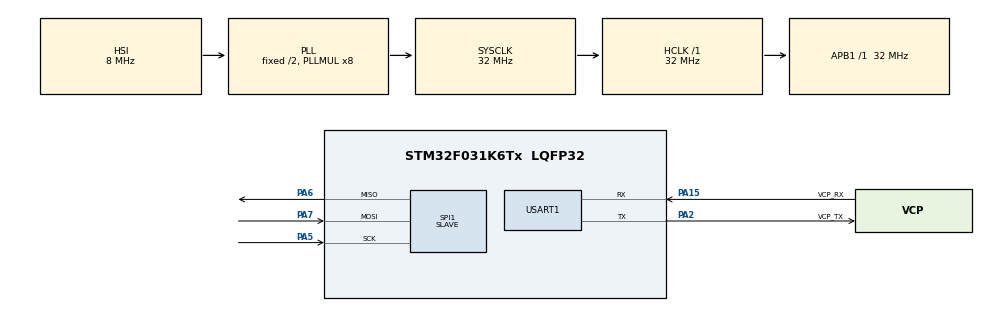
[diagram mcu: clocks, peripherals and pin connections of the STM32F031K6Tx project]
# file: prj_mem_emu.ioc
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Mcu.Family=STM32F0
Mcu.Name=STM32F031K6Tx
Mcu.Package=LQFP32
PA13.GPIO_Label=SWDIO
PA13.Mode=Serial_Wire
PA13.Signal=SYS_SWDIO
PA14.GPIO_Label=SWCLK
PA14.Mode=Serial_Wire
PA14.Signal=SYS_SWCLK
PA15.GPIO_Label=VCP_RX
PA15.Mode=Asynchronous
PA15.Signal=USART1_RX
PA2.GPIO_Label=VCP_TX
PA2.Mode=Asynchronous
PA2.Signal=USART1_TX
PA5.Mode=Full_Duplex_Slave
PA5.Signal=SPI1_SCK
PA6.Mode=Full_Duplex_Slave
PA6.Signal=SPI1_MISO
PA7.Mode=Full_Duplex_Slave
PA7.Signal=SPI1_MOSI
PF0-OSC_IN.Mode=HSE-External-Clock-Source
PF0-OSC_IN.Signal=RCC_OSC_IN
ProjectManager.HeapSize=0x200
ProjectManager.StackSize=0x400
ProjectManager.TargetToolchain=STM32CubeIDE
RCC.AHBFreq_Value=32000000
RCC.APB1Freq_Value=32000000
RCC.APB1TimFreq_Value=32000000
RCC.HCLKFreq_Value=32000000
RCC.PLLMUL=RCC_PLL_MUL8
RCC.SYSCLKFreq_VALUE=32000000
RCC.SYSCLKSource=RCC_SYSCLKSOURCE_PLLCLK
SPI1.DataSize=SPI_DATASIZE_8BIT
SPI1.Direction=SPI_DIRECTION_2LINES
SPI1.Mode=SPI_MODE_SLAVE
SPI1.VirtualType=VM_SLAVE
USART1.VirtualMode-Asynchronous=VM_ASYNC
board=NUCLEO-F031K6

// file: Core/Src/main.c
/* USER CODE BEGIN Header */
/**
  ******************************************************************************
  * @file           : main.c
  * @brief          : Main program body
  ******************************************************************************
  * @attention
  *
  * Copyright (c) 2023 STMicroelectronics.
  * All rights reserved.
  *
  * This software is licensed under terms that can be found in the LICENSE file
  * in the root directory of this software component.
  * If no LICENSE file comes with this software, it is provided AS-IS.
  *
  ******************************************************************************
  */
/* USER CODE END Header */
#include "main.h"

SPI_HandleTypeDef hspi1;

UART_HandleTypeDef huart1;

void SystemClock_Config(void);
static void MX_GPIO_Init(void);
static void MX_USART1_UART_Init(void);
static void MX_SPI1_Init(void);

/* USER CODE BEGIN 0 */
#define MEM_SIZE (256U)
/* USER CODE END 0 */

int main(void)
{
  /* USER CODE BEGIN 1 */
	uint8_t mem[MEM_SIZE];
	uint8_t rxdata[3];
	uint32_t index = 0;
  /* USER CODE END 1 */

  /* MCU Configuration--------------------------------------------------------*/

  /* Reset of all peripherals, Initializes the Flash interface and the Systick. */
  HAL_Init();

  /* Configure the system clock */
  SystemClock_Config();

  /* Initialize all configured peripherals */
  MX_GPIO_Init();
  MX_USART1_UART_Init();
  MX_SPI1_Init();

  /* Infinite loop */
  /* USER CODE BEGIN WHILE */
  while (1)
  {
	  HAL_SPI_Receive(&hspi1, rxdata, 2, HAL_MAX_DELAY);
	  if(rxdata[0] == 0x02){
		  HAL_SPI_Receive(&hspi1, rxdata + 2, 1, HAL_MAX_DELAY);
		  mem[rxdata[1] % MEM_SIZE] = rxdata[2];
	  }else if(rxdata[0] == 0x03){
		  HAL_SPI_Transmit(&hspi1, &(mem[rxdata[1] % MEM_SIZE]), 1, HAL_MAX_DELAY);
	  }
    /* USER CODE END WHILE */

  }
}

void SystemClock_Config(void)
{
  RCC_OscInitTypeDef RCC_OscInitStruct = {0};
  RCC_ClkInitTypeDef RCC_ClkInitStruct = {0};
  RCC_PeriphCLKInitTypeDef PeriphClkInit = {0};

  /** Initializes the RCC Oscillators according to the specified parameters
  * in the RCC_OscInitTypeDef structure.
  */
  RCC_OscInitStruct.OscillatorType = RCC_OSCILLATORTYPE_HSI;
  RCC_OscInitStruct.HSIState = RCC_HSI_ON;
  RCC_OscInitStruct.HSICalibrationValue = RCC_HSICALIBRATION_DEFAULT;
  RCC_OscInitStruct.PLL.PLLState = RCC_PLL_ON;
  RCC_OscInitStruct.PLL.PLLSource = RCC_PLLSOURCE_HSI;
  RCC_OscInitStruct.PLL.PLLMUL = RCC_PLL_MUL8;
  RCC_OscInitStruct.PLL.PREDIV = RCC_PREDIV_DIV1;
  if (HAL_RCC_OscConfig(&RCC_OscInitStruct) != HAL_OK)
  {
    Error_Handler();
  }

  /** Initializes the CPU, AHB and APB buses clocks
  */
  RCC_ClkInitStruct.ClockType = RCC_CLOCKTYPE_HCLK|RCC_CLOCKTYPE_SYSCLK
                              |RCC_CLOCKTYPE_PCLK1;
  RCC_ClkInitStruct.SYSCLKSource = RCC_SYSCLKSOURCE_PLLCLK;
  RCC_ClkInitStruct.AHBCLKDivider = RCC_SYSCLK_DIV1;
  RCC_ClkInitStruct.APB1CLKDivider = RCC_HCLK_DIV1;

  if (HAL_RCC_ClockConfig(&RCC_ClkInitStruct, FLASH_LATENCY_1) != HAL_OK)
  {
    Error_Handler();
  }
  PeriphClkInit.PeriphClockSelection = RCC_PERIPHCLK_USART1;
  PeriphClkInit.Usart1ClockSelection = RCC_USART1CLKSOURCE_PCLK1;
  if (HAL_RCCEx_PeriphCLKConfig(&PeriphClkInit) != HAL_OK)
  {
    Error_Handler();
  }
}

static void MX_SPI1_Init(void)
{

  /* SPI1 parameter configuration*/
  hspi1.Instance = SPI1;
  hspi1.Init.Mode = SPI_MODE_SLAVE;
  hspi1.Init.Direction = SPI_DIRECTION_2LINES;
  hspi1.Init.DataSize = SPI_DATASIZE_8BIT;
  hspi1.Init.CLKPolarity = SPI_POLARITY_LOW;
  hspi1.Init.CLKPhase = SPI_PHASE_1EDGE;
  hspi1.Init.NSS = SPI_NSS_SOFT;
  hspi1.Init.FirstBit = SPI_FIRSTBIT_MSB;
  hspi1.Init.TIMode = SPI_TIMODE_DISABLE;
  hspi1.Init.CRCCalculation = SPI_CRCCALCULATION_DISABLE;
  hspi1.Init.CRCPolynomial = 7;
  hspi1.Init.CRCLength = SPI_CRC_LENGTH_DATASIZE;
  hspi1.Init.NSSPMode = SPI_NSS_PULSE_DISABLE;
  if (HAL_SPI_Init(&hspi1) != HAL_OK)
  {
    Error_Handler();
  }

}

static void MX_USART1_UART_Init(void)
{

  huart1.Instance = USART1;
  huart1.Init.BaudRate = 38400;
  huart1.Init.WordLength = UART_WORDLENGTH_8B;
  huart1.Init.StopBits = UART_STOPBITS_1;
  huart1.Init.Parity = UART_PARITY_NONE;
  huart1.Init.Mode = UART_MODE_TX_RX;
  huart1.Init.HwFlowCtl = UART_HWCONTROL_NONE;
  huart1.Init.OverSampling = UART_OVERSAMPLING_16;
  huart1.Init.OneBitSampling = UART_ONE_BIT_SAMPLE_DISABLE;
  huart1.AdvancedInit.AdvFeatureInit = UART_ADVFEATURE_NO_INIT;
  if (HAL_UART_Init(&huart1) != HAL_OK)
  {
    Error_Handler();
  }

}

static void MX_GPIO_Init(void)
{

  /* GPIO Ports Clock Enable */
  __HAL_RCC_GPIOF_CLK_ENABLE();
  __HAL_RCC_GPIOA_CLK_ENABLE();

}

void Error_Handler(void)
{
  __disable_irq();
  while (1)
  {
  }
}
